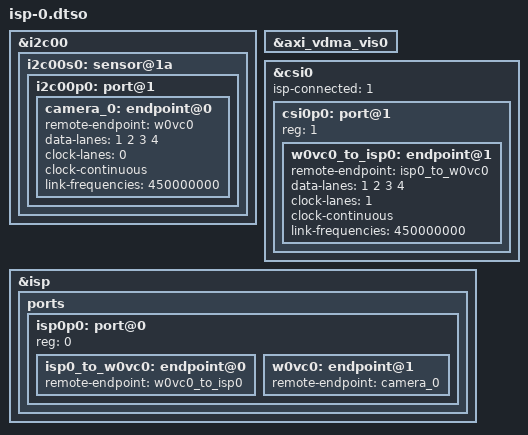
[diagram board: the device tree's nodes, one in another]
// SPDX-License-Identifier: (GPL-2.0+ OR MIT)
/*
 * Copyright (c) 2024 SiMa ai
 */

/dts-v1/;
/plugin/;

&i2c00 {
	i2c00s0: sensor@1a {
		i2c00p0: port@1 {
			camera_0: endpoint@0 {
				remote-endpoint = <&w0vc0>;
				data-lanes = <1 2 3 4>;
				clock-lanes = <0>;
				clock-continuous;
				link-frequencies = /bits/ 64 <450000000>;
			};
		};
	};
};

&axi_vdma_vis0 {
	status = "okay";
};

&csi0 {
	status = "okay";
	isp-connected = <1>;
	csi0p0: port@1 {
		reg = <1>;
		w0vc0_to_isp0: endpoint@1 {
			remote-endpoint = <&isp0_to_w0vc0>;
			data-lanes = <1 2 3 4>;
			clock-lanes = <1>;
			clock-continuous;
			link-frequencies = /bits/ 64 <450000000>;
		};
	};
};

&isp {
	status = "okay";
	ports {
		#address-cells = <1>;
		#size-cells = <0>;
		isp0p0: port@0 {
			reg = <0>;
			isp0_to_w0vc0: endpoint@0 {
				remote-endpoint = <&w0vc0_to_isp0>;
			};
			w0vc0: endpoint@1 {
				remote-endpoint = <&camera_0>;
			};
		};
	};
};
